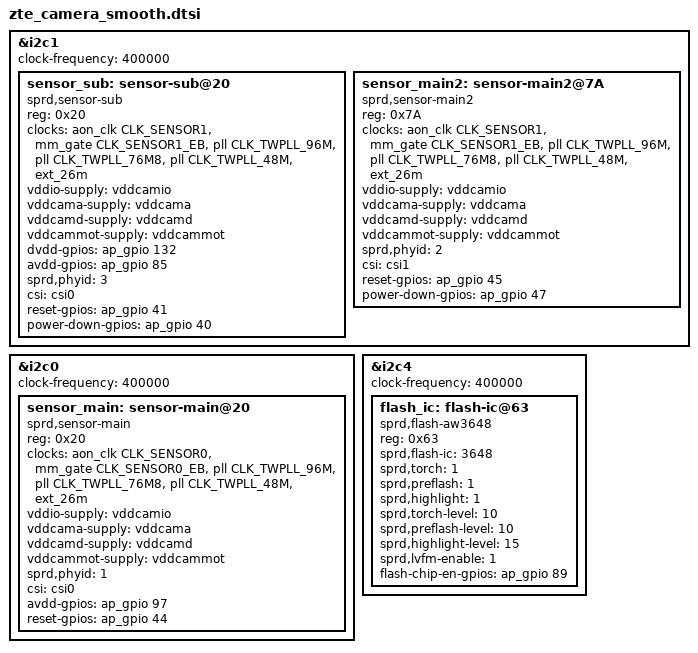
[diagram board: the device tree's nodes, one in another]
&i2c1 {
	/delete-node/ sensor-sub@20;
};

&i2c1 {
	/delete-node/ sensor-main2@6C;
};
&i2c1 {
	status = "okay";
	clock-frequency = <400000>;

	sensor_sub: sensor-sub@20 {
		compatible = "sprd,sensor-sub";
		reg = <0x20>;
		clock-names = "clk_src","sensor_eb",
			"clk_96m","clk_76m8",
			"clk_48m","clk_26m";
		/*clocks = <&clk_sensor1>, <&clk_mckg_gates 6>,
			<&clk_twpll_96m>,<&clk_twpll_76m8>,
			<&clk_twpll_48m>,<&ext_26m>;*/
		clocks = <&aon_clk CLK_SENSOR1>, <&mm_gate CLK_SENSOR1_EB>,
			<&pll CLK_TWPLL_96M>,<&pll CLK_TWPLL_76M8>,
			<&pll CLK_TWPLL_48M>,<&ext_26m>;
		vddio-supply = <&vddcamio>;
		vddcama-supply = <&vddcama>;
		vddcamd-supply = <&vddcamd>;
		vddcammot-supply = <&vddcammot>;
		dvdd-gpios=<&ap_gpio 132 0>;
		avdd-gpios=<&ap_gpio 85 0>;
		sprd,phyid = <3>;
		csi = <&csi0>;
		reset-gpios = <&ap_gpio 41 0>;
		power-down-gpios = <&ap_gpio 40 0>;
	};
	sensor_main2: sensor-main2@7A {
		compatible = "sprd,sensor-main2";
		reg = <0x7A>;
		clock-names = "clk_src","sensor_eb",
			"clk_96m","clk_76m8",
			"clk_48m","clk_26m";
		/*clocks = <&clk_sensor1>, <&clk_mckg_gates 6>,
			<&clk_twpll_96m>,<&clk_twpll_76m8>,
			<&clk_twpll_48m>,<&ext_26m>;*/
		clocks = <&aon_clk CLK_SENSOR1>, <&mm_gate CLK_SENSOR1_EB>,
			<&pll CLK_TWPLL_96M>,<&pll CLK_TWPLL_76M8>,
			<&pll CLK_TWPLL_48M>,<&ext_26m>;
		vddio-supply = <&vddcamio>;
		vddcama-supply = <&vddcama>;
		vddcamd-supply = <&vddcamd>;
		vddcammot-supply = <&vddcammot>;
		sprd,phyid = <2>;
		csi = <&csi1>;
		/*avdd-gpios=<&ap_gpio 140 0>;*/
		reset-gpios = <&ap_gpio 45 0>;
		power-down-gpios = <&ap_gpio 47 0>;
	};
};


&i2c0 {
	/delete-node/ sensor-main@20;
};

&i2c0 {
	status = "okay";
	clock-frequency = <400000>;

	sensor_main: sensor-main@20 {
		compatible = "sprd,sensor-main";
		reg = <0x20>;
		clock-names = "clk_src","sensor_eb",
			"clk_96m","clk_76m8",
			"clk_48m","clk_26m";
		clocks = <&aon_clk CLK_SENSOR0>, <&mm_gate CLK_SENSOR0_EB>,
			<&pll CLK_TWPLL_96M>,<&pll CLK_TWPLL_76M8>,
			<&pll CLK_TWPLL_48M>,<&ext_26m>;
		vddio-supply = <&vddcamio>;
		vddcama-supply = <&vddcama>;
		vddcamd-supply = <&vddcamd>;
		vddcammot-supply = <&vddcammot>;
		sprd,phyid = <1>;
		csi = <&csi0>;
		avdd-gpios=<&ap_gpio 97 0>;
		reset-gpios = <&ap_gpio 44 0>;
	};
};

&i2c4 {
	/delete-node/ flash-ic@63;
};
&i2c4 {
	status = "okay";
	clock-frequency = <400000>;

	flash_ic: flash-ic@63 {
		compatible = "sprd,flash-aw3648";
		reg = <0x63>;
		sprd,flash-ic = <3648>;
		sprd,torch = <1>;
		sprd,preflash = <1>;
		sprd,highlight = <1>;
		sprd,torch-level = <10>;
		sprd,preflash-level = <10>;
		sprd,highlight-level = <15>;
		sprd,lvfm-enable = <1>;
		/*flash-en-gpios = <&ap_gpio 89 0>;*/
		flash-chip-en-gpios = <&ap_gpio 89 0>;
	};
};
